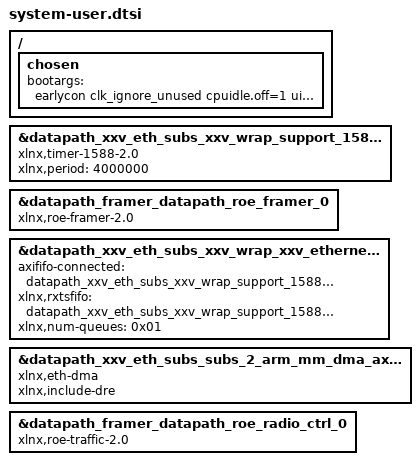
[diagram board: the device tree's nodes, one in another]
/include/ "system-conf.dtsi"
/ {
    chosen {
       bootargs = "earlycon clk_ignore_unused cpuidle.off=1 uio_pdrv_genirq.of_id=generic-uio";
    };
};
&datapath_xxv_eth_subs_xxv_wrap_support_1588_2step_timer1588_subs_timer_1588_v2_0_0 {
    compatible = "xlnx,timer-1588-2.0";
    xlnx,period = <4000000>;
};
&datapath_framer_datapath_roe_framer_0 {
    compatible = "xlnx,roe-framer-2.0","xlnx,roe-framer-1.0";
};
&datapath_xxv_eth_subs_xxv_wrap_xxv_ethernet_0 {
    axififo-connected = <&datapath_xxv_eth_subs_xxv_wrap_support_1588_2step_tx_ts_fifo_axi_fifo_mm_s_0>;
    xlnx,rxtsfifo = <&datapath_xxv_eth_subs_xxv_wrap_support_1588_2step_rx_ts_fifo_axi_fifo_mm_s_0>;
    xlnx,num-queues = /bits/ 16 <0x01>;
};
&datapath_xxv_eth_subs_subs_2_arm_mm_dma_axi_dma_0 {
  compatible = "xlnx,eth-dma";
  xlnx,include-dre;  
};
&datapath_framer_datapath_roe_radio_ctrl_0 {
    compatible = "xlnx,roe-traffic-2.0";    
};
